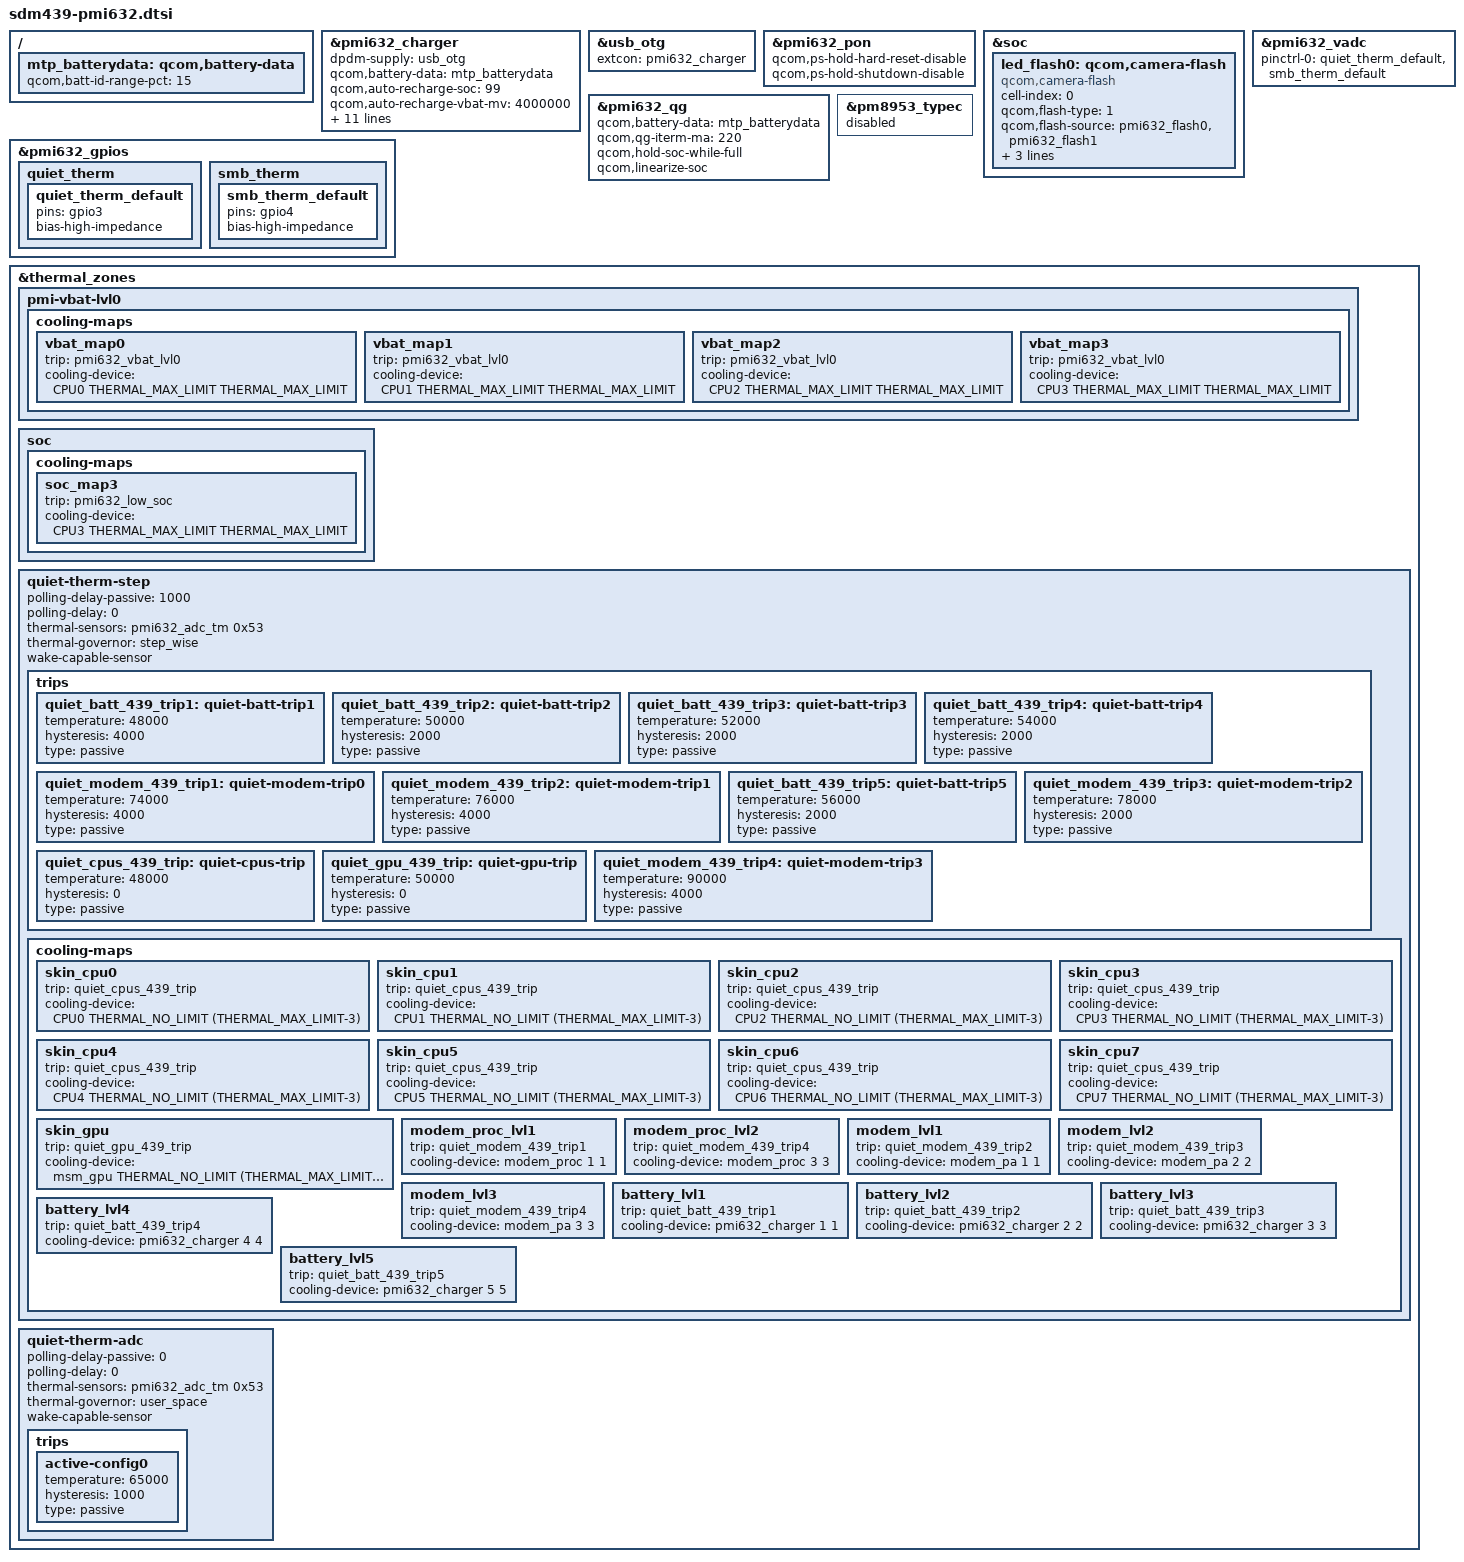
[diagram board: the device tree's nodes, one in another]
#include "pmi632.dtsi"

&pmi632_charger {
	dpdm-supply = <&usb_otg>;
	qcom,battery-data = <&mtp_batterydata>;

	//+Bug601084, yangpingao.wt, modify, 2020/11/15, P81081 charger bring up
	qcom,auto-recharge-soc = <99>;
	qcom,auto-recharge-vbat-mv = <4000000>;
	qcom,flash-disable-soc = <10>;
	qcom,fcc-max-ua = <1500000>;
	qcom,fv-max-uv = <4400000>;
	qcom,usb-icl-ua = <1500000>;
	qcom,otg-cl-ua = <1000000>;
	qcom,sw-jeita-enable;
	qcom,chg-term-src = <1>;
	qcom,chg-term-current-ma = <(-150)>;
	/*qcom,step-charging-enable;*/
	//-Bug601084, yangpingao.wt, modify, 2020/11/15, P81081 charger bring up
	//+Bug 439935 xushengjuan.wt,modify,20201112,S86117AA1 charger bring up
	//qcom,hw-die-temp-mitigation;
	//qcom,hw-connector-mitigation;
	//-Bug 439935 xushengjuan.wt,modify,20201112,S86117AA1 charger bring up
	qcom,connector-internal-pull-kohm = <100>;
	//+Bug601084, yangpingao.wt, modify, 2020/11/15, P81081 charger bring up
	qcom,thermal-mitigation
	    = <2000000 2000000 2000000 1500000
		1000000 500000>;
};

&usb_otg {
	extcon = <&pmi632_charger>;
};

&pmi632_pon {
	qcom,ps-hold-hard-reset-disable;
	qcom,ps-hold-shutdown-disable;
};

&soc {
	led_flash0: qcom,camera-flash {
		cell-index = <0>;
		compatible = "qcom,camera-flash";
		qcom,flash-type = <1>;
		qcom,flash-source = <&pmi632_flash0 &pmi632_flash1>;
		qcom,torch-source = <&pmi632_torch0 &pmi632_torch1>;
		qcom,switch-source = <&pmi632_switch0>;
	};
};

/ {
	mtp_batterydata: qcom,battery-data {
		qcom,batt-id-range-pct = <15>;
		//#include "qg-batterydata-ascent-3450mah.dtsi"
		//#include "qg-batterydata-mlp356477-2800mah.dtsi"
		//+Bug601084, yangpingao.wt, modify, 2020/11/15, P81081 charger bring up
		#include "batterydata-wingtech-Sunwoda-4v4-4980mah.dtsi"
		#include "batterydata-wingtech-Scud-4v4-4980mah.dtsi"
		#include "batterydata-wingtech-Jiade-4v4-4980mah.dtsi"
		//-Bug601084, yangpingao.wt, modify, 2020/11/15, P81081 charger bring up
	};
};

&pmi632_qg {
	qcom,battery-data = <&mtp_batterydata>;
	//+Bug601084, yangpingao.wt, modify, 2020/11/15, modifiy low probability quick recharger
	qcom,qg-iterm-ma = <220>;
	qcom,hold-soc-while-full;
	qcom,linearize-soc;
};

&pmi632_vadc {
	pinctrl-names = "default";
	pinctrl-0 = <&quiet_therm_default &smb_therm_default>;
};

&pmi632_gpios {
	quiet_therm {
		quiet_therm_default: quiet_therm_default {
			pins = "gpio3";
			bias-high-impedance;
		};
	};

	smb_therm {
		smb_therm_default: smb_therm_default {
			pins = "gpio4";
			bias-high-impedance;
		};
	};
};

&pm8953_typec {
	status = "disabled";
};

&thermal_zones {
	pmi-vbat-lvl0 {
		cooling-maps {
			vbat_map0 {
				trip = <&pmi632_vbat_lvl0>;
				cooling-device =
					<&CPU0 THERMAL_MAX_LIMIT
						THERMAL_MAX_LIMIT>;
			};

			vbat_map1 {
				trip = <&pmi632_vbat_lvl0>;
				cooling-device =
					<&CPU1 THERMAL_MAX_LIMIT
						THERMAL_MAX_LIMIT>;
			};

			vbat_map2 {
				trip = <&pmi632_vbat_lvl0>;
				cooling-device =
					<&CPU2 THERMAL_MAX_LIMIT
						THERMAL_MAX_LIMIT>;
			};

			vbat_map3 {
				trip = <&pmi632_vbat_lvl0>;
				cooling-device =
					<&CPU3 THERMAL_MAX_LIMIT
						THERMAL_MAX_LIMIT>;
			};
		};
	};

	soc {
		cooling-maps {
	//+Extb P210423-03864, chenwende.wt, Modify, 20210510, modify the func of offline cpu -- only offline cpu3.
			/*soc_map0 {
				trip = <&pmi632_low_soc>;
				cooling-device =
					<&CPU0 THERMAL_MAX_LIMIT
						THERMAL_MAX_LIMIT>;
			};

			soc_map1 {
				trip = <&pmi632_low_soc>;
				cooling-device =
					<&CPU1 THERMAL_MAX_LIMIT
						THERMAL_MAX_LIMIT>;
			};

			soc_map2 {
				trip = <&pmi632_low_soc>;
				cooling-device =
					<&CPU2 THERMAL_MAX_LIMIT
						THERMAL_MAX_LIMIT>;
			};*/
	//-Extb P210423-03864, chenwende.wt, Modify, 20210510, modify the func of offline cpu -- only offline cpu3.
			soc_map3 {
				trip = <&pmi632_low_soc>;
				cooling-device =
					<&CPU3 THERMAL_MAX_LIMIT
						THERMAL_MAX_LIMIT>;
			};

		};
	};

	quiet-therm-step {
		polling-delay-passive = <1000>;
		polling-delay = <0>;
		thermal-sensors = <&pmi632_adc_tm 0x53>;
		thermal-governor = "step_wise";
		wake-capable-sensor;
/*+Extb P210423-03864, chenwende.wt, Modify, 20210510, N8R-Modify the thermal thresholds of modem and battery */
		trips {
			quiet_batt_439_trip1: quiet-batt-trip1 {
				temperature = <48000>;
				hysteresis = <4000>;
				type = "passive";
			};

			quiet_batt_439_trip2: quiet-batt-trip2 {
				temperature = <50000>;
				hysteresis = <2000>;
				type = "passive";
			};

			quiet_batt_439_trip3: quiet-batt-trip3 {
				temperature = <52000>;
				hysteresis = <2000>;
				type = "passive";
			};

			quiet_batt_439_trip4: quiet-batt-trip4 {
				temperature = <54000>;
				hysteresis = <2000>;
				type = "passive";
			};

			quiet_modem_439_trip1: quiet-modem-trip0 {
				temperature = <74000>;
				hysteresis = <4000>;
				type = "passive";
			};

			quiet_modem_439_trip2: quiet-modem-trip1 {
				temperature = <76000>;
				hysteresis = <4000>;
				type = "passive";
			};

			quiet_batt_439_trip5: quiet-batt-trip5 {
				temperature = <56000>;
				hysteresis = <2000>;
				type = "passive";
			};

			quiet_modem_439_trip3: quiet-modem-trip2 {
				temperature = <78000>;
				hysteresis = <2000>;
				type = "passive";
			};

			quiet_cpus_439_trip: quiet-cpus-trip {
				temperature = <48000>;
				hysteresis = <0>;
				type = "passive";
			};

			quiet_gpu_439_trip: quiet-gpu-trip {
				temperature = <50000>;
				hysteresis = <0>;
				type = "passive";
			};
/*
			quiet_batt_439_trip7: quiet-batt-trip7 {
				temperature = <50000>;
				hysteresis = <2000>;
				type = "passive";
			};
*/
			quiet_modem_439_trip4: quiet-modem-trip3 {
				temperature = <90000>;
				hysteresis = <4000>;
				type = "passive";
			};
		};

		cooling-maps {
			skin_cpu0 {
				trip = <&quiet_cpus_439_trip>;
				/* throttle from fmax to 1497600KHz */
				cooling-device = <&CPU0 THERMAL_NO_LIMIT
							(THERMAL_MAX_LIMIT-3)>;
			};

			skin_cpu1 {
				trip = <&quiet_cpus_439_trip>;
				cooling-device = <&CPU1 THERMAL_NO_LIMIT
							(THERMAL_MAX_LIMIT-3)>;
			};

			skin_cpu2 {
				trip = <&quiet_cpus_439_trip>;
				cooling-device = <&CPU2 THERMAL_NO_LIMIT
							(THERMAL_MAX_LIMIT-3)>;
			};

			skin_cpu3 {
				trip = <&quiet_cpus_439_trip>;
				cooling-device = <&CPU3 THERMAL_NO_LIMIT
							(THERMAL_MAX_LIMIT-3)>;
			};

			skin_cpu4 {
				trip = <&quiet_cpus_439_trip>;
				/* throttle from fmax to 1171200KHz */
				cooling-device = <&CPU4 THERMAL_NO_LIMIT
							(THERMAL_MAX_LIMIT-3)>;
			};

			skin_cpu5 {
				trip = <&quiet_cpus_439_trip>;
				cooling-device = <&CPU5 THERMAL_NO_LIMIT
							(THERMAL_MAX_LIMIT-3)>;
			};

			skin_cpu6 {
				trip = <&quiet_cpus_439_trip>;
				cooling-device = <&CPU6 THERMAL_NO_LIMIT
							(THERMAL_MAX_LIMIT-3)>;
			};

			skin_cpu7 {
				trip = <&quiet_cpus_439_trip>;
				cooling-device = <&CPU7 THERMAL_NO_LIMIT
							(THERMAL_MAX_LIMIT-3)>;
			};

			skin_gpu {
				trip = <&quiet_gpu_439_trip>;
				/* throttle from fmax to 510000000Hz */
				cooling-device = <&msm_gpu THERMAL_NO_LIMIT
							(THERMAL_MAX_LIMIT-2)>;
			};

			modem_proc_lvl1 {
				trip = <&quiet_modem_439_trip1>;
				cooling-device = <&modem_proc 1 1>;
			};

			modem_proc_lvl2 {
				trip = <&quiet_modem_439_trip4>;
				cooling-device = <&modem_proc 3 3>;
			};

			modem_lvl1 {
				trip = <&quiet_modem_439_trip2>;
				cooling-device = <&modem_pa 1 1>;
			};

			modem_lvl2 {
				trip = <&quiet_modem_439_trip3>;
				cooling-device = <&modem_pa 2 2>;
			};

			modem_lvl3 {
				trip = <&quiet_modem_439_trip4>;
				cooling-device = <&modem_pa 3 3>;
			};

			battery_lvl1 {
				trip = <&quiet_batt_439_trip1>;
				cooling-device = <&pmi632_charger 1 1>;
			};

			battery_lvl2 {
				trip = <&quiet_batt_439_trip2>;
				cooling-device = <&pmi632_charger 2 2>;
			};

			battery_lvl3 {
				trip = <&quiet_batt_439_trip3>;
				cooling-device = <&pmi632_charger 3 3>;
			};

			battery_lvl4 {
				trip = <&quiet_batt_439_trip4>;
				cooling-device = <&pmi632_charger 4 4>;
			};

			battery_lvl5 {
				trip = <&quiet_batt_439_trip5>;
				cooling-device = <&pmi632_charger 5 5>;
			};
/*
			battery_lvl6 {
				trip = <&quiet_439_batt_trip6_mdm_trip3>;
				cooling-device = <&pmi632_charger 6 6>;
			};

			battery_lvl7 {
				trip = <&quiet_batt_439_trip7>;
				cooling-device = <&pmi632_charger 7 7>;
			};
*/
/*-Extb P210423-03864, chenwende.wt, Modify, 20210510, N8R-Modify the thermal thresholds of modem and battery */
		};
	};

	quiet-therm-adc {
		polling-delay-passive = <0>;
		polling-delay = <0>;
		thermal-sensors = <&pmi632_adc_tm 0x53>;
		thermal-governor = "user_space";
		wake-capable-sensor;

		trips {
			active-config0 {
				temperature = <65000>;
				hysteresis = <1000>;
				type = "passive";
			};
		};
	};
};
